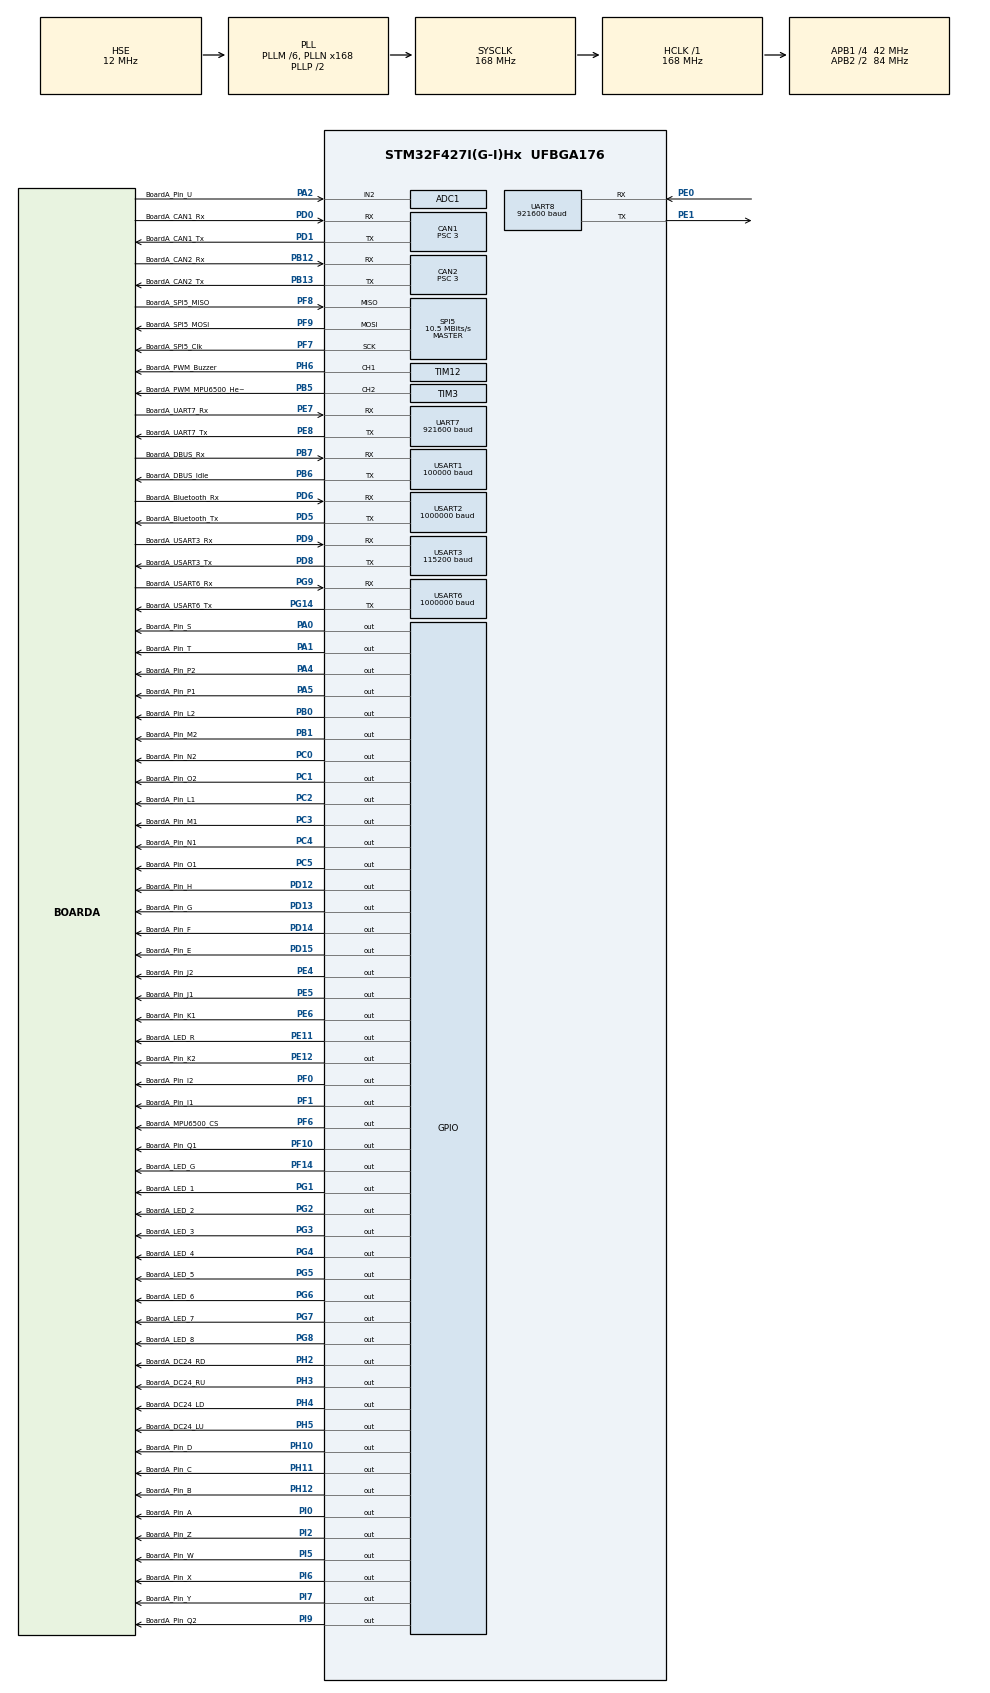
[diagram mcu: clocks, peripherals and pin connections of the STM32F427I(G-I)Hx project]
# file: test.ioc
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ADC1.Channel-0\#ChannelRegularConversion=ADC_CHANNEL_2
ADC1.ClockPrescaler=ADC_CLOCK_SYNC_PCLK_DIV8
ADC1.ContinuousConvMode=ENABLE
ADC1.DMAContinuousRequests=ENABLE
ADC1.NbrOfConversionFlag=1
ADC1.Rank-0\#ChannelRegularConversion=1
ADC1.SamplingTime-0\#ChannelRegularConversion=ADC_SAMPLETIME_480CYCLES
ADC1.ScanConvMode=ENABLE
ADC1.master=1
CAN1.ABOM=ENABLE
CAN1.BS1=CAN_BS1_7TQ
CAN1.BS2=CAN_BS2_6TQ
CAN1.CalculateBaudRate=1000000
CAN1.CalculateTimeBit=1000
CAN1.CalculateTimeQuantum=71.42857142857143
CAN1.NART=ENABLE
CAN1.Prescaler=3
CAN2.ABOM=ENABLE
CAN2.BS1=CAN_BS1_7TQ
CAN2.BS2=CAN_BS2_6TQ
CAN2.CalculateBaudRate=1000000
CAN2.CalculateTimeBit=1000
CAN2.CalculateTimeQuantum=71.42857142857143
CAN2.NART=ENABLE
CAN2.Prescaler=3
Dma.ADC1.7.Direction=DMA_PERIPH_TO_MEMORY
Dma.ADC1.7.FIFOMode=DMA_FIFOMODE_DISABLE
Dma.ADC1.7.Instance=DMA2_Stream0
Dma.ADC1.7.MemDataAlignment=DMA_MDATAALIGN_HALFWORD
Dma.ADC1.7.MemInc=DMA_MINC_ENABLE
Dma.ADC1.7.Mode=DMA_CIRCULAR
Dma.ADC1.7.PeriphDataAlignment=DMA_PDATAALIGN_HALFWORD
Dma.ADC1.7.PeriphInc=DMA_PINC_DISABLE
Dma.ADC1.7.Priority=DMA_PRIORITY_LOW
Dma.Request0=USART1_RX
Dma.Request1=USART2_RX
Dma.Request10=SPI5_TX
Dma.Request2=USART6_RX
Dma.Request3=USART6_TX
Dma.Request4=USART3_RX
Dma.Request5=USART3_TX
Dma.Request6=UART7_RX
Dma.Request7=ADC1
Dma.Request8=UART8_RX
Dma.Request9=SPI5_RX
Dma.SPI5_RX.9.Direction=DMA_PERIPH_TO_MEMORY
Dma.SPI5_RX.9.FIFOMode=DMA_FIFOMODE_ENABLE
Dma.SPI5_RX.9.FIFOThreshold=DMA_FIFO_THRESHOLD_FULL
Dma.SPI5_RX.9.Instance=DMA2_Stream3
Dma.SPI5_RX.9.MemBurst=DMA_MBURST_SINGLE
Dma.SPI5_RX.9.MemDataAlignment=DMA_MDATAALIGN_BYTE
Dma.SPI5_RX.9.MemInc=DMA_MINC_ENABLE
Dma.SPI5_RX.9.Mode=DMA_NORMAL
Dma.SPI5_RX.9.PeriphBurst=DMA_PBURST_SINGLE
Dma.SPI5_RX.9.PeriphDataAlignment=DMA_PDATAALIGN_BYTE
Dma.SPI5_RX.9.PeriphInc=DMA_PINC_DISABLE
Dma.SPI5_RX.9.Priority=DMA_PRIORITY_LOW
Dma.SPI5_TX.10.Direction=DMA_MEMORY_TO_PERIPH
Dma.SPI5_TX.10.FIFOMode=DMA_FIFOMODE_ENABLE
Dma.SPI5_TX.10.FIFOThreshold=DMA_FIFO_THRESHOLD_FULL
Dma.SPI5_TX.10.Instance=DMA2_Stream4
Dma.SPI5_TX.10.MemBurst=DMA_MBURST_SINGLE
Dma.SPI5_TX.10.MemDataAlignment=DMA_MDATAALIGN_BYTE
Dma.SPI5_TX.10.MemInc=DMA_MINC_ENABLE
Dma.SPI5_TX.10.Mode=DMA_NORMAL
Dma.SPI5_TX.10.PeriphBurst=DMA_PBURST_SINGLE
Dma.SPI5_TX.10.PeriphDataAlignment=DMA_PDATAALIGN_BYTE
Dma.SPI5_TX.10.PeriphInc=DMA_PINC_DISABLE
Dma.SPI5_TX.10.Priority=DMA_PRIORITY_LOW
Dma.UART7_RX.6.Direction=DMA_PERIPH_TO_MEMORY
Dma.UART7_RX.6.FIFOMode=DMA_FIFOMODE_ENABLE
Dma.UART7_RX.6.FIFOThreshold=DMA_FIFO_THRESHOLD_FULL
Dma.UART7_RX.6.Instance=DMA1_Stream3
Dma.UART7_RX.6.MemBurst=DMA_MBURST_SINGLE
Dma.UART7_RX.6.MemDataAlignment=DMA_MDATAALIGN_BYTE
Dma.UART7_RX.6.MemInc=DMA_MINC_ENABLE
Dma.UART7_RX.6.Mode=DMA_NORMAL
Dma.UART7_RX.6.PeriphBurst=DMA_PBURST_SINGLE
Dma.UART7_RX.6.PeriphDataAlignment=DMA_PDATAALIGN_BYTE
Dma.UART7_RX.6.PeriphInc=DMA_PINC_DISABLE
Dma.UART7_RX.6.Priority=DMA_PRIORITY_LOW
Dma.UART8_RX.8.Direction=DMA_PERIPH_TO_MEMORY
Dma.UART8_RX.8.FIFOMode=DMA_FIFOMODE_DISABLE
Dma.UART8_RX.8.Instance=DMA1_Stream6
Dma.UART8_RX.8.MemDataAlignment=DMA_MDATAALIGN_BYTE
Dma.UART8_RX.8.MemInc=DMA_MINC_ENABLE
Dma.UART8_RX.8.Mode=DMA_NORMAL
Dma.UART8_RX.8.PeriphDataAlignment=DMA_PDATAALIGN_BYTE
Dma.UART8_RX.8.PeriphInc=DMA_PINC_DISABLE
Dma.UART8_RX.8.Priority=DMA_PRIORITY_LOW
Dma.USART1_RX.0.Direction=DMA_PERIPH_TO_MEMORY
Dma.USART1_RX.0.FIFOMode=DMA_FIFOMODE_ENABLE
Dma.USART1_RX.0.FIFOThreshold=DMA_FIFO_THRESHOLD_FULL
Dma.USART1_RX.0.Instance=DMA2_Stream2
Dma.USART1_RX.0.MemBurst=DMA_MBURST_SINGLE
Dma.USART1_RX.0.MemDataAlignment=DMA_MDATAALIGN_BYTE
Dma.USART1_RX.0.MemInc=DMA_MINC_ENABLE
Dma.USART1_RX.0.Mode=DMA_NORMAL
Dma.USART1_RX.0.PeriphBurst=DMA_PBURST_SINGLE
Dma.USART1_RX.0.PeriphDataAlignment=DMA_PDATAALIGN_BYTE
Dma.USART1_RX.0.PeriphInc=DMA_PINC_DISABLE
Dma.USART1_RX.0.Priority=DMA_PRIORITY_LOW
Dma.USART2_RX.1.Direction=DMA_PERIPH_TO_MEMORY
Dma.USART2_RX.1.FIFOMode=DMA_FIFOMODE_ENABLE
Dma.USART2_RX.1.FIFOThreshold=DMA_FIFO_THRESHOLD_FULL
Dma.USART2_RX.1.Instance=DMA1_Stream5
Dma.USART2_RX.1.MemBurst=DMA_MBURST_SINGLE
Dma.USART2_RX.1.MemDataAlignment=DMA_MDATAALIGN_BYTE
Dma.USART2_RX.1.MemInc=DMA_MINC_ENABLE
Dma.USART2_RX.1.Mode=DMA_NORMAL
Dma.USART2_RX.1.PeriphBurst=DMA_PBURST_SINGLE
Dma.USART2_RX.1.PeriphDataAlignment=DMA_PDATAALIGN_BYTE
Dma.USART2_RX.1.PeriphInc=DMA_PINC_DISABLE
Dma.USART2_RX.1.Priority=DMA_PRIORITY_LOW
Dma.USART3_RX.4.Direction=DMA_PERIPH_TO_MEMORY
Dma.USART3_RX.4.FIFOMode=DMA_FIFOMODE_ENABLE
Dma.USART3_RX.4.FIFOThreshold=DMA_FIFO_THRESHOLD_FULL
Dma.USART3_RX.4.Instance=DMA1_Stream1
Dma.USART3_RX.4.MemBurst=DMA_MBURST_SINGLE
Dma.USART3_RX.4.MemDataAlignment=DMA_MDATAALIGN_BYTE
Dma.USART3_RX.4.MemInc=DMA_MINC_ENABLE
Dma.USART3_RX.4.Mode=DMA_NORMAL
Dma.USART3_RX.4.PeriphBurst=DMA_PBURST_SINGLE
Dma.USART3_RX.4.PeriphDataAlignment=DMA_PDATAALIGN_BYTE
Dma.USART3_RX.4.PeriphInc=DMA_PINC_DISABLE
Dma.USART3_RX.4.Priority=DMA_PRIORITY_LOW
Dma.USART3_TX.5.Direction=DMA_MEMORY_TO_PERIPH
Dma.USART3_TX.5.FIFOMode=DMA_FIFOMODE_ENABLE
Dma.USART3_TX.5.FIFOThreshold=DMA_FIFO_THRESHOLD_FULL
Dma.USART3_TX.5.Instance=DMA1_Stream4
Dma.USART3_TX.5.MemBurst=DMA_MBURST_SINGLE
Dma.USART3_TX.5.MemDataAlignment=DMA_MDATAALIGN_BYTE
Dma.USART3_TX.5.MemInc=DMA_MINC_ENABLE
Dma.USART3_TX.5.Mode=DMA_NORMAL
Dma.USART3_TX.5.PeriphBurst=DMA_PBURST_SINGLE
Dma.USART3_TX.5.PeriphDataAlignment=DMA_PDATAALIGN_BYTE
Dma.USART3_TX.5.PeriphInc=DMA_PINC_DISABLE
Dma.USART3_TX.5.Priority=DMA_PRIORITY_LOW
Dma.USART6_RX.2.Direction=DMA_PERIPH_TO_MEMORY
Dma.USART6_RX.2.FIFOMode=DMA_FIFOMODE_ENABLE
Dma.USART6_RX.2.FIFOThreshold=DMA_FIFO_THRESHOLD_FULL
Dma.USART6_RX.2.Instance=DMA2_Stream1
Dma.USART6_RX.2.MemBurst=DMA_MBURST_SINGLE
Dma.USART6_RX.2.MemDataAlignment=DMA_MDATAALIGN_BYTE
Dma.USART6_RX.2.MemInc=DMA_MINC_ENABLE
Dma.USART6_RX.2.Mode=DMA_NORMAL
Dma.USART6_RX.2.PeriphBurst=DMA_PBURST_SINGLE
Dma.USART6_RX.2.PeriphDataAlignment=DMA_PDATAALIGN_BYTE
Dma.USART6_RX.2.PeriphInc=DMA_PINC_DISABLE
Dma.USART6_RX.2.Priority=DMA_PRIORITY_LOW
Dma.USART6_TX.3.Direction=DMA_MEMORY_TO_PERIPH
Dma.USART6_TX.3.FIFOMode=DMA_FIFOMODE_ENABLE
Dma.USART6_TX.3.FIFOThreshold=DMA_FIFO_THRESHOLD_FULL
Dma.USART6_TX.3.Instance=DMA2_Stream6
Dma.USART6_TX.3.MemBurst=DMA_MBURST_SINGLE
Dma.USART6_TX.3.MemDataAlignment=DMA_MDATAALIGN_BYTE
Dma.USART6_TX.3.MemInc=DMA_MINC_ENABLE
Dma.USART6_TX.3.Mode=DMA_NORMAL
Dma.USART6_TX.3.PeriphBurst=DMA_PBURST_SINGLE
Dma.USART6_TX.3.PeriphDataAlignment=DMA_PDATAALIGN_BYTE
Dma.USART6_TX.3.PeriphInc=DMA_PINC_DISABLE
Dma.USART6_TX.3.Priority=DMA_PRIORITY_LOW
Mcu.Family=STM32F4
Mcu.Name=STM32F427I(G-I)Hx
Mcu.Package=UFBGA176
NVIC.ADC_IRQn=true\:0\:0\:false\:false\:true\:true\:true\:true
NVIC.CAN1_RX0_IRQn=true\:0\:0\:true\:false\:true\:true\:true\:true
NVIC.CAN1_RX1_IRQn=true\:0\:0\:true\:false\:true\:true\:true\:true
NVIC.CAN2_RX0_IRQn=true\:0\:0\:false\:false\:true\:true\:true\:true
NVIC.CAN2_RX1_IRQn=true\:0\:0\:false\:false\:true\:true\:true\:true
NVIC.DMA1_Stream1_IRQn=true\:0\:0\:false\:false\:true\:false\:true\:true
NVIC.DMA1_Stream3_IRQn=true\:0\:0\:false\:false\:true\:false\:true\:true
NVIC.DMA1_Stream4_IRQn=true\:0\:0\:false\:false\:true\:false\:true\:true
NVIC.DMA1_Stream5_IRQn=true\:0\:0\:false\:false\:true\:false\:true\:true
NVIC.DMA1_Stream6_IRQn=true\:0\:0\:false\:false\:true\:false\:true\:true
NVIC.DMA2_Stream0_IRQn=true\:0\:0\:false\:false\:true\:false\:true\:true
NVIC.DMA2_Stream1_IRQn=true\:0\:0\:false\:false\:true\:false\:true\:true
NVIC.DMA2_Stream2_IRQn=true\:0\:0\:false\:false\:true\:false\:true\:true
NVIC.DMA2_Stream3_IRQn=true\:0\:0\:false\:false\:true\:false\:true\:true
NVIC.DMA2_Stream4_IRQn=true\:0\:0\:false\:false\:true\:false\:true\:true
NVIC.DMA2_Stream6_IRQn=true\:0\:0\:false\:false\:true\:false\:true\:true
NVIC.PriorityGroup=NVIC_PRIORITYGROUP_4
NVIC.SPI5_IRQn=true\:0\:0\:false\:false\:true\:true\:true\:true
NVIC.TIM4_IRQn=true\:1\:0\:true\:false\:true\:true\:true\:true
NVIC.TIM5_IRQn=true\:1\:0\:true\:false\:true\:true\:true\:true
NVIC.UART7_IRQn=true\:0\:0\:false\:false\:true\:true\:true\:true
NVIC.UART8_IRQn=true\:0\:0\:false\:false\:true\:true\:true\:true
NVIC.USART1_IRQn=true\:0\:0\:false\:false\:true\:true\:true\:true
NVIC.USART2_IRQn=true\:0\:0\:false\:false\:true\:true\:true\:true
NVIC.USART3_IRQn=true\:0\:0\:false\:false\:true\:true\:true\:true
NVIC.USART6_IRQn=true\:0\:0\:false\:false\:true\:true\:true\:true
PA0/WKUP.GPIO_Label=BoardA_Pin_S
PA0/WKUP.Signal=GPIO_Output
PA1.GPIO_Label=BoardA_Pin_T
PA1.Signal=GPIO_Output
PA13.Mode=Serial_Wire
PA13.Signal=SYS_JTMS-SWDIO
PA14.Mode=Serial_Wire
PA14.Signal=SYS_JTCK-SWCLK
PA2.GPIO_Label=BoardA_Pin_U
PA2.Signal=ADCx_IN2
PA4.GPIO_Label=BoardA_Pin_P2
PA4.Signal=GPIO_Output
PA5.GPIO_Label=BoardA_Pin_P1
PA5.Signal=GPIO_Output
PB0.GPIO_Label=BoardA_Pin_L2
PB0.Signal=GPIO_Output
PB1.GPIO_Label=BoardA_Pin_M2
PB1.Signal=GPIO_Output
PB12.GPIO_Label=BoardA_CAN2_Rx
PB12.Mode=CAN_Activate
PB12.Signal=CAN2_RX
PB13.GPIO_Label=BoardA_CAN2_Tx
PB13.Mode=CAN_Activate
PB13.Signal=CAN2_TX
PB5.GPIO_Label=BoardA_PWM_MPU6500_Heater
PB5.Signal=S_TIM3_CH2
PB6.GPIO_Label=BoardA_DBUS_Idle
PB6.Mode=Asynchronous
PB6.Signal=USART1_TX
PB7.GPIO_Label=BoardA_DBUS_Rx
PB7.Mode=Asynchronous
PB7.Signal=USART1_RX
PC0.GPIO_Label=BoardA_Pin_N2
PC0.Signal=GPIO_Output
PC1.GPIO_Label=BoardA_Pin_O2
PC1.Signal=GPIO_Output
PC2.GPIO_Label=BoardA_Pin_L1
PC2.Signal=GPIO_Output
PC3.GPIO_Label=BoardA_Pin_M1
PC3.Signal=GPIO_Output
PC4.GPIO_Label=BoardA_Pin_N1
PC4.Signal=GPIO_Output
PC5.GPIO_Label=BoardA_Pin_O1
PC5.Signal=GPIO_Output
PD0.GPIO_Label=BoardA_CAN1_Rx
PD0.Mode=CAN_Activate
PD0.Signal=CAN1_RX
PD1.GPIO_Label=BoardA_CAN1_Tx
PD1.Mode=CAN_Activate
PD1.Signal=CAN1_TX
PD12.GPIO_Label=BoardA_Pin_H
PD12.Signal=GPIO_Output
PD13.GPIO_Label=BoardA_Pin_G
PD13.Signal=GPIO_Output
PD14.GPIO_Label=BoardA_Pin_F
PD14.Signal=GPIO_Output
PD15.GPIO_Label=BoardA_Pin_E
PD15.Signal=GPIO_Output
PD5.GPIO_Label=BoardA_Bluetooth_Tx
PD5.Mode=Asynchronous
PD5.Signal=USART2_TX
PD6.GPIO_Label=BoardA_Bluetooth_Rx
PD6.Mode=Asynchronous
PD6.Signal=USART2_RX
PD8.GPIO_Label=BoardA_USART3_Tx
PD8.Mode=Asynchronous
PD8.Signal=USART3_TX
PD9.GPIO_Label=BoardA_USART3_Rx
PD9.Mode=Asynchronous
PD9.Signal=USART3_RX
PE0.Mode=Asynchronous
PE0.Signal=UART8_RX
PE1.Mode=Asynchronous
PE1.Signal=UART8_TX
PE11.GPIO_Label=BoardA_LED_R
PE11.GPIO_PuPd=GPIO_NOPULL
PE11.PinState=GPIO_PIN_SET
PE11.Signal=GPIO_Output
PE12.GPIO_Label=BoardA_Pin_K2
PE12.Signal=GPIO_Output
PE4.GPIO_Label=BoardA_Pin_J2
PE4.Signal=GPIO_Output
PE5.GPIO_Label=BoardA_Pin_J1
PE5.Signal=GPIO_Output
PE6.GPIO_Label=BoardA_Pin_K1
PE6.Signal=GPIO_Output
PE7.GPIO_Label=BoardA_UART7_Rx
PE7.Mode=Asynchronous
PE7.Signal=UART7_RX
PE8.GPIO_Label=BoardA_UART7_Tx
PE8.Mode=Asynchronous
PE8.Signal=UART7_TX
PF0.GPIO_Label=BoardA_Pin_I2
PF0.Signal=GPIO_Output
PF1.GPIO_Label=BoardA_Pin_I1
PF1.Signal=GPIO_Output
PF10.GPIO_Label=BoardA_Pin_Q1
PF10.Signal=GPIO_Output
PF14.GPIO_Label=BoardA_LED_G
PF14.GPIO_PuPd=GPIO_NOPULL
PF14.PinState=GPIO_PIN_SET
PF14.Signal=GPIO_Output
PF6.GPIO_Label=BoardA_MPU6500_CS
PF6.GPIO_Speed=GPIO_SPEED_FREQ_VERY_HIGH
PF6.PinState=GPIO_PIN_SET
PF6.Signal=GPIO_Output
PF7.GPIO_Label=BoardA_SPI5_Clk
PF7.Mode=Full_Duplex_Master
PF7.Signal=SPI5_SCK
PF8.GPIO_Label=BoardA_SPI5_MISO
PF8.Mode=Full_Duplex_Master
PF8.Signal=SPI5_MISO
PF9.GPIO_Label=BoardA_SPI5_MOSI
PF9.Mode=Full_Duplex_Master
PF9.Signal=SPI5_MOSI
PG1.GPIO_Label=BoardA_LED_1
PG1.GPIO_PuPd=GPIO_NOPULL
PG1.PinState=GPIO_PIN_SET
PG1.Signal=GPIO_Output
PG14.GPIO_Label=BoardA_USART6_Tx
PG14.Mode=Asynchronous
PG14.Signal=USART6_TX
PG2.GPIO_Label=BoardA_LED_2
PG2.GPIO_PuPd=GPIO_NOPULL
PG2.PinState=GPIO_PIN_SET
PG2.Signal=GPIO_Output
PG3.GPIO_Label=BoardA_LED_3
PG3.GPIO_PuPd=GPIO_NOPULL
PG3.Signal=GPIO_Output
PG4.GPIO_Label=BoardA_LED_4
PG4.GPIO_PuPd=GPIO_NOPULL
PG4.PinState=GPIO_PIN_SET
PG4.Signal=GPIO_Output
PG5.GPIO_Label=BoardA_LED_5
PG5.GPIO_PuPd=GPIO_NOPULL
PG5.PinState=GPIO_PIN_SET
PG5.Signal=GPIO_Output
PG6.GPIO_Label=BoardA_LED_6
PG6.GPIO_PuPd=GPIO_NOPULL
PG6.PinState=GPIO_PIN_SET
PG6.Signal=GPIO_Output
PG7.GPIO_Label=BoardA_LED_7
PG7.GPIO_PuPd=GPIO_NOPULL
PG7.PinState=GPIO_PIN_SET
PG7.Signal=GPIO_Output
PG8.GPIO_Label=BoardA_LED_8
PG8.GPIO_PuPd=GPIO_NOPULL
PG8.PinState=GPIO_PIN_SET
PG8.Signal=GPIO_Output
PG9.GPIO_Label=BoardA_USART6_Rx
PG9.Mode=Asynchronous
PG9.Signal=USART6_RX
PH0/OSC_IN.Mode=HSE-External-Oscillator
PH0/OSC_IN.Signal=RCC_OSC_IN
PH1/OSC_OUT.Mode=HSE-External-Oscillator
PH1/OSC_OUT.Signal=RCC_OSC_OUT
PH10.GPIO_Label=BoardA_Pin_D
PH10.Signal=GPIO_Output
PH11.GPIO_Label=BoardA_Pin_C
PH11.Signal=GPIO_Output
PH12.GPIO_Label=BoardA_Pin_B
PH12.Signal=GPIO_Output
PH2.GPIO_Label=BoardA_DC24_RD
PH2.GPIO_PuPd=GPIO_NOPULL
PH2.Signal=GPIO_Output
PH3.GPIO_Label=BoardA_DC24_RU
PH3.GPIO_PuPd=GPIO_NOPULL
PH3.Signal=GPIO_Output
PH4.GPIO_Label=BoardA_DC24_LD
PH4.GPIO_PuPd=GPIO_NOPULL
PH4.Signal=GPIO_Output
PH5.GPIO_Label=BoardA_DC24_LU
PH5.GPIO_PuPd=GPIO_NOPULL
PH5.Signal=GPIO_Output
PH6.GPIO_Label=BoardA_PWM_Buzzer
PH6.Signal=S_TIM12_CH1
PI0.GPIO_Label=BoardA_Pin_A
PI0.Signal=GPIO_Output
PI2.GPIO_Label=BoardA_Pin_Z
PI2.Signal=GPIO_Output
PI5.GPIO_Label=BoardA_Pin_W
PI5.Signal=GPIO_Output
PI6.GPIO_Label=BoardA_Pin_X
PI6.Signal=GPIO_Output
PI7.GPIO_Label=BoardA_Pin_Y
PI7.Signal=GPIO_Output
PI9.GPIO_Label=BoardA_Pin_Q2
PI9.Signal=GPIO_Output
ProjectManager.HeapSize=0x400
ProjectManager.StackSize=0x10000
ProjectManager.TargetToolchain=MDK-ARM V5.32
RCC.48MHZClocksFreq_Value=48000000
RCC.AHBFreq_Value=168000000
RCC.APB1CLKDivider=RCC_HCLK_DIV4
RCC.APB1Freq_Value=42000000
RCC.APB1TimFreq_Value=84000000
RCC.APB2CLKDivider=RCC_HCLK_DIV2
RCC.APB2Freq_Value=84000000
RCC.APB2TimFreq_Value=168000000
RCC.CortexFreq_Value=168000000
RCC.HCLKFreq_Value=168000000
RCC.HSE_VALUE=12000000
RCC.HSI_VALUE=16000000
RCC.LSE_VALUE=32768
RCC.PLLM=6
RCC.PLLN=168
RCC.PLLQ=7
RCC.PLLSourceVirtual=RCC_PLLSOURCE_HSE
RCC.SYSCLKFreq_VALUE=168000000
RCC.SYSCLKSource=RCC_SYSCLKSOURCE_PLLCLK
RCC.VCOOutputFreq_Value=336000000
SH.ADCx_IN2.0=ADC1_IN2,IN2
SH.S_TIM12_CH1.0=TIM12_CH1,PWM Generation1 CH1
SH.S_TIM3_CH2.0=TIM3_CH2,PWM Generation2 CH2
SPI5.BaudRatePrescaler=SPI_BAUDRATEPRESCALER_8
SPI5.CLKPhase=SPI_PHASE_2EDGE
SPI5.CLKPolarity=SPI_POLARITY_HIGH
SPI5.CalculateBaudRate=10.5 MBits/s
SPI5.Direction=SPI_DIRECTION_2LINES
SPI5.Mode=SPI_MODE_MASTER
SPI5.VirtualType=VM_MASTER
STMicroelectronics.X-CUBE-ALGOBUILD.1.4.0.LibraryCcDSPOoLibraryJjDSPOoLibrary=true
TIM12.Channel-PWM\ Generation1\ CH1=TIM_CHANNEL_1
TIM12.Period=5600
TIM12.Prescaler=100/9-1
TIM3.Channel-PWM\ Generation2\ CH2=TIM_CHANNEL_2
TIM4.Period=100-1
TIM4.Prescaler=84-1
TIM5.Period=1000-1
TIM5.Prescaler=84-1
UART7.BaudRate=921600
UART7.VirtualMode=Asynchronous
UART8.BaudRate=921600
UART8.VirtualMode=Asynchronous
USART1.BaudRate=100000
USART1.Mode=MODE_RX
USART1.Parity=PARITY_EVEN
USART1.VirtualMode=VM_ASYNC
USART1.WordLength=WORDLENGTH_9B
USART2.BaudRate=1000000
USART2.Parity=PARITY_NONE
USART2.VirtualMode=VM_ASYNC
USART3.BaudRate=115200
USART3.VirtualMode=VM_ASYNC
USART6.BaudRate=1000000
USART6.VirtualMode=VM_ASYNC
VP_STMicroelectronics.X-CUBE-ALGOBUILD_VS_DSPOoLibraryJjLibrary_1.4.0_1.4.0.Mode=DSPOoLibraryJjLibrary
VP_TIM4_VS_ClockSourceINT.Mode=Internal
VP_TIM5_VS_ClockSourceINT.Mode=Internal
board=custom

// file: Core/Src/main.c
/* USER CODE BEGIN Header */
/**
 ******************************************************************************
 * @file           : main.c
 * @brief          : Main program body
 ******************************************************************************
 * @attention
 *
 * Copyright (c) 2024 STMicroelectronics.
 * All rights reserved.
 *
 * This software is licensed under terms that can be found in the LICENSE file
 * in the root directory of this software component.
 * If no LICENSE file comes with this software, it is provided AS-IS.
 *
 ******************************************************************************
 */
/* USER CODE END Header */
#include "main.h"
#include "adc.h"
#include "can.h"
#include "dma.h"
#include "spi.h"
#include "tim.h"
#include "usart.h"
#include "gpio.h"

/* USER CODE BEGIN Includes */

#include "1_Middleware/1_Driver/BSP/drv_djiboarda.h"

#include "2_Device/Motor/Motor_DJI/dvc_motor_dji.h"
#include "2_Device/Serialplot/dvc_serialplot.h"
#include "2_Device/Powermeter/dvc_powermeter.h"

/* USER CODE END Includes */

/* USER CODE BEGIN PV */

bool init_finished = 0;

Class_Serialplot serialplot;
Class_Powermeter powermeter;
Class_Motor_DJI_C620 motor;

int32_t Counter = 0;

/* USER CODE END PV */

void SystemClock_Config(void);

/* USER CODE BEGIN 0 */

/**
 * @brief CAN报文回调函数
 *
 * @param Rx_Buffer CAN接收的信息结构体
 */
void CAN_Motor_Call_Back(Struct_CAN_Rx_Buffer *Rx_Buffer)
{
    switch (Rx_Buffer->Header.StdId)
    {
    case (0x201):
    {
        motor.CAN_RxCpltCallback(Rx_Buffer->Data);
    }
    }
}

/**
 * @brief HAL库UART接收DMA空闲中断
 *
 * @param huart UART编号
 * @param Size 长度
 */
void UART_Serialplot_Call_Back(uint8_t *Buffer, uint16_t Length)
{
}

/**
 * @brief HAL库UART接收DMA空闲中断
 *
 * @param huart UART编号
 * @param Size 长度
 */
void UART_Powermeter_Call_Back(uint8_t *Buffer, uint16_t Length)
{
    powermeter.UART_RxCpltCallback(Buffer, Length);
}

/* USER CODE END 0 */

int main(void)
{

    /* MCU Configuration--------------------------------------------------------*/

    /* Reset of all peripherals, Initializes the Flash interface and the Systick. */
    HAL_Init();

    /* Configure the system clock */
    SystemClock_Config();

    /* Initialize all configured peripherals */
    MX_GPIO_Init();
    MX_DMA_Init();
    MX_CAN2_Init();
    MX_TIM3_Init();
    MX_TIM4_Init();
    MX_TIM5_Init();
    MX_TIM12_Init();
    MX_CAN1_Init();
    MX_USART1_UART_Init();
    MX_USART2_UART_Init();
    MX_USART3_UART_Init();
    MX_USART6_UART_Init();
    MX_UART7_Init();
    MX_UART8_Init();
    MX_ADC1_Init();
    MX_SPI5_Init();
    /* USER CODE BEGIN 2 */

    BSP_Init(BSP_DC24_LU_ON | BSP_DC24_LD_ON | BSP_DC24_RU_ON | BSP_DC24_RD_ON);
    CAN_Init(&hcan1, CAN_Motor_Call_Back);
    UART_Init(&huart2, UART_Serialplot_Call_Back, SERIALPLOT_RX_VARIABLE_ASSIGNMENT_MAX_LENGTH);
    UART_Init(&huart6, UART_Powermeter_Call_Back, 20);

    serialplot.Init(&huart2, Serialplot_Checksum_8_ENABLE, NULL);
    powermeter.Init(&huart6);

    motor.PID_Omega.Init(0.15f, 0.0f, 0.0f, 0.0f, 20.0f, 20.0f);
    motor.Init(&hcan1, Motor_DJI_ID_0x201, Motor_DJI_Control_Method_CURRENT, 1.0f);

    init_finished = 1;

    /* USER CODE END 2 */

    /* Infinite loop */
    /* USER CODE BEGIN WHILE */
    while (1)
    {
        Counter++;
        if(Counter < 2000)
        {
            motor.Set_Control_Method(Motor_DJI_Control_Method_OMEGA);
            motor.Set_Target_Omega(-200.0f);
        }
        else if(Counter < 4000)
        {
            motor.Set_Control_Method(Motor_DJI_Control_Method_OMEGA);
            motor.Set_Target_Omega(-100.0f);
        }
        else if(Counter < 6000)
        {
            motor.Set_Control_Method(Motor_DJI_Control_Method_OMEGA);
            motor.Set_Target_Omega(-50.0f);
        }
        else if(Counter < 8000)
        {
            motor.Set_Control_Method(Motor_DJI_Control_Method_OMEGA);
            motor.Set_Target_Omega(-20.0f);
        }
        else if(Counter < 10000)
        {
            motor.Set_Control_Method(Motor_DJI_Control_Method_OMEGA);
            motor.Set_Target_Omega(-10.0f);
        }
        else if(Counter < 12000)
        {
            motor.Set_Control_Method(Motor_DJI_Control_Method_OMEGA);
            motor.Set_Target_Omega(0.0f);
        }
        else if(Counter < 14000)
        {
            motor.Set_Control_Method(Motor_DJI_Control_Method_OMEGA);
            motor.Set_Target_Omega(10.0f);
        }
        else if(Counter < 16000)
        {
            motor.Set_Control_Method(Motor_DJI_Control_Method_OMEGA);
            motor.Set_Target_Omega(20.0f);
        }
        else if(Counter < 18000)
        {
            motor.Set_Control_Method(Motor_DJI_Control_Method_OMEGA);
            motor.Set_Target_Omega(50.0f);
        }
        else if(Counter < 20000)
        {
            motor.Set_Control_Method(Motor_DJI_Control_Method_OMEGA);
            motor.Set_Target_Omega(100.0f);
        }
        else if(Counter < 22000)
        {
            motor.Set_Control_Method(Motor_DJI_Control_Method_OMEGA);
            motor.Set_Target_Omega(200.0f);
        }
        else if(Counter < 26000)
        {
            motor.Set_Control_Method(Motor_DJI_Control_Method_CURRENT);
            motor.Set_Target_Current(1.0f * sinf(10.0f * PI * (Counter - 22000) / 1000.0f));
        }
        else if(Counter < 30000)
        {
            motor.Set_Control_Method(Motor_DJI_Control_Method_CURRENT);
            motor.Set_Target_Current(2.0f * sinf(10.0f * PI * (Counter - 22000) / 1000.0f));
        }
        else if(Counter < 34000)
        {
            motor.Set_Control_Method(Motor_DJI_Control_Method_CURRENT);
            motor.Set_Target_Current(5.0f * sinf(10.0f * PI * (Counter - 22000) / 1000.0f));
        }
        else
        {
            Counter = 0;
        }

        // 保持存活
        static uint32_t Counter_KeepAlive = 0;
        if (Counter_KeepAlive++ > 100)
        {
            Counter_KeepAlive = 0;

            motor.TIM_100ms_Alive_PeriodElapsedCallback();
        }

        // 串口绘图显示内容

        float now_power = powermeter.Get_Power();
        // k0: 0.6641993412640775
        // k1: 0.006444284468539646
        // k2: 0.0001423857226262331
        // k3: 0.017644430204543864
        // k4: 0.1650143850678086
        // k5: 3.096721772539512e-05
        // k0 + k1 * I + k2 * ω + k3 * I * ω + k4 * I^2 + k5 * ω^2
        float estimate_power = 0.6641993412640775f + 0.006444284468539646f * motor.Get_Now_Current() + 0.0001423857226262331f * motor.Get_Now_Omega() + 0.017644430204543864f * motor.Get_Now_Current() * motor.Get_Now_Omega() + 0.1650143850678086f * motor.Get_Now_Current() * motor.Get_Now_Current() + 3.096721772539512e-05f * motor.Get_Now_Omega() * motor.Get_Now_Omega();
        serialplot.Set_Data(2, &now_power, &estimate_power);
        serialplot.TIM_1ms_Write_PeriodElapsedCallback();

        // 电机控制
        motor.TIM_Calculate_PeriodElapsedCallback();

        // 通信设备回调数据
        TIM_1ms_CAN_PeriodElapsedCallback();

        // 延时1ms
        HAL_Delay(0);
        /* USER CODE END WHILE */

    }
}

void SystemClock_Config(void)
{
    RCC_OscInitTypeDef RCC_OscInitStruct = {0};
    RCC_ClkInitTypeDef RCC_ClkInitStruct = {0};

    /** Configure the main internal regulator output voltage
     */
    __HAL_RCC_PWR_CLK_ENABLE();
    __HAL_PWR_VOLTAGESCALING_CONFIG(PWR_REGULATOR_VOLTAGE_SCALE1);

    /** Initializes the RCC Oscillators according to the specified parameters
     * in the RCC_OscInitTypeDef structure.
     */
    RCC_OscInitStruct.OscillatorType = RCC_OSCILLATORTYPE_HSE;
    RCC_OscInitStruct.HSEState = RCC_HSE_ON;
    RCC_OscInitStruct.PLL.PLLState = RCC_PLL_ON;
    RCC_OscInitStruct.PLL.PLLSource = RCC_PLLSOURCE_HSE;
    RCC_OscInitStruct.PLL.PLLM = 6;
    RCC_OscInitStruct.PLL.PLLN = 168;
    RCC_OscInitStruct.PLL.PLLP = RCC_PLLP_DIV2;
    RCC_OscInitStruct.PLL.PLLQ = 7;
    if (HAL_RCC_OscConfig(&RCC_OscInitStruct) != HAL_OK)
    {
        Error_Handler();
    }

    /** Initializes the CPU, AHB and APB buses clocks
     */
    RCC_ClkInitStruct.ClockType = RCC_CLOCKTYPE_HCLK | RCC_CLOCKTYPE_SYSCLK | RCC_CLOCKTYPE_PCLK1 | RCC_CLOCKTYPE_PCLK2;
    RCC_ClkInitStruct.SYSCLKSource = RCC_SYSCLKSOURCE_PLLCLK;
    RCC_ClkInitStruct.AHBCLKDivider = RCC_SYSCLK_DIV1;
    RCC_ClkInitStruct.APB1CLKDivider = RCC_HCLK_DIV4;
    RCC_ClkInitStruct.APB2CLKDivider = RCC_HCLK_DIV2;

    if (HAL_RCC_ClockConfig(&RCC_ClkInitStruct, FLASH_LATENCY_5) != HAL_OK)
    {
        Error_Handler();
    }
}

void Error_Handler(void)
{
    __disable_irq();
    while (1)
    {
    }
}
